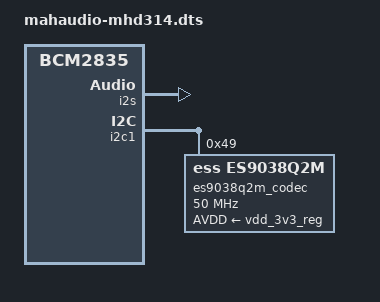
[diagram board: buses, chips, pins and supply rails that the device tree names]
/dts-v1/;
/plugin/;

/ {
    compatible = "brcm,bcm2835";

    fragment@0 {
        target = <&i2s>;
        __overlay__ {
            status = "okay";
        };
    };

    fragment@1 {
        target = <&i2c1>;
        __overlay__ {
            #address-cells = <1>;
            #size-cells = <0>;
            status = "okay";

            es9038q2m_codec: es9038q2m-codec@49 {
                compatible = "ess,es9038q2m";
                status = "okay";
                reg = <0x49>;
                clock-frequency = <50000000>;
                AVDD-supply = <&vdd_3v3_reg>;
                #sound-dai-cells = <0>;
            };
        };
    };

    fragment@3 {
        target = <&sound>;
        sound_overlay: __overlay__ {
            compatible = "simple-audio-card";
            status = "okay";
            simple-audio-card,format = "left_j";
            simple-audio-card,name = "mhd314";
            simple-audio-card,bitclock-master = <&dailink0_master>;
            simple-audio-card,frame-master = <&dailink0_master>;
            dai-tdm-slot-num = <2>;
            dai-tdm-slot-width = <16>;

            simple-audio-card,cpu {
                sound-dai = <&i2s>;
            };
            dailink0_master: simple-audio-card,codec {
                sound-dai = <&es9038q2m_codec>;
            };
        };
    };
};
